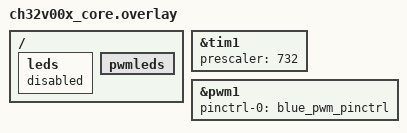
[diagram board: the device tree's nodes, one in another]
/*
 * SPDX-FileCopyrightText: Copyright Michael Hope <michaelh@juju.nz>
 *
 * SPDX-License-Identifier: Apache-2.0
 */

/ {
	leds {
		status = "disabled";
	};

	pwmleds {
		status = "okay";
	};
};

&tim1 {
	status = "okay";
	/*
	 * The sample runs from 1 Hz to 128 Hz, ceil(48 MHz / 65536 / 1 Hz)
	 * is 733, and the prescaler property is one less than that.
	 */
	prescaler = <732>;
};

&pwm1 {
	status = "okay";
	pinctrl-0 = <&blue_pwm_pinctrl>;
	pinctrl-names = "default";
};
